AUTOSAR XML (schema 4-3-0)
package /ComponentTypes
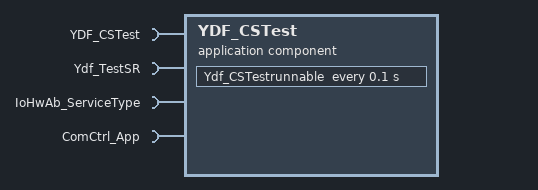
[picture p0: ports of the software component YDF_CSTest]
  application sw component type YDF_CSTest
    4 x require port:
      YDF_CSTest: client-com-spec=Element, required-interface=YDF_CSTest
      Ydf_TestSR: required-com-specs=[{data-element=TestSender1, init-value=0}, {data-element=TestSender2, init-value=0}], required-interface=Ydf_TestSR
      IoHwAb_ServiceType: required-interface=IoHwAb_ServiceType
        required-com-specs:
          IoHwAb_DioGetChannelVal
          IoHwAb_DioSetChannelVal
          IoHwAb_AdcConvert12BitValueTomv
          IoHwAb_AdcGetChannelValue
          IoHwAb_AdcReadValues
      ComCtrl_App: nonqueued-receiver-com-spec{data-element=ComState, filter=data-filter-type=ALWAYS, init-value=0}, required-interface=ComCtrl_App
    behavior YDF_CSTest_InternalBehavior
      timing event TMT_Ydf_CSTestrunnable: start-on-event=Ydf_CSTestrunnable, period=0.1
      runnable Ydf_CSTestrunnable
        data-receive-point-by-arguments:
          access REC_Ydf_TestSR_TestSender1: accessed-variable=Ydf_TestSR.TestSender1
          access REC_Ydf_TestSR_TestSender2: accessed-variable=Ydf_TestSR.TestSender2
          access REC_ComCtrl_App_ComState: accessed-variable=ComCtrl_App.ComState
        6 x sync call:
          SC_IoHwAb_ServiceType_IoHwAb_AdcConvert12BitValueTomv: operation=IoHwAb_ServiceType.IoHwAb_AdcConvert12BitValueTomv
          SC_IoHwAb_ServiceType_IoHwAb_AdcGetChannelValue: operation=IoHwAb_ServiceType.IoHwAb_AdcGetChannelValue
          SC_IoHwAb_ServiceType_IoHwAb_AdcReadValues: operation=IoHwAb_ServiceType.IoHwAb_AdcReadValues
          SC_IoHwAb_ServiceType_IoHwAb_DioGetChannelVal: operation=IoHwAb_ServiceType.IoHwAb_DioGetChannelVal
          SC_IoHwAb_ServiceType_IoHwAb_DioSetChannelVal: operation=IoHwAb_ServiceType.IoHwAb_DioSetChannelVal
          SC_YDF_CSTest_Element: operation=YDF_CSTest.Element
  swc implementation YDF_CSTest_Implementation: behavior=YDF_CSTest_InternalBehavior
